VERSION ""

NS_ :

BS_:

BU_:
VAL_TABLE_ Parking_Light_VT 1 "Parking Lights Blinking" 0 "Parking lights OFF" ;
VAL_TABLE_ Indicator_Light_VT 1 "Left or Right Indicator ON" 0 "Left or Right Indicator OFF" ;
VAL_TABLE_ Ignition_Key_VT 3 "Car started" 2 "Pre-Ignition phase" 1 "Key Inserted" 0 "Key not inserted" ;
VAL_TABLE_ Engine_VT 1 "Engine RUNNING" 0 "Engine IDLE" ;
VAL_TABLE_ Brake_VT 1 "Brake Applied" 0 "Brake Not Applied" ;
VAL_TABLE_ Gear_VT 3 "Parking" 2 "Reverse" 1 "Drive" 0 "Neutral" ;

BO_ 260 Vehicle_Motion: 4 Vector__XXX
 SG_ Vehicle_Speed : 16|16@1+ (0.1,0) [0|6553.5] "m/s" Vector__XXX
 SG_ Engine_Status : 0|1@1+ (1,0) [0|1] "Boolean" Vector__XXX

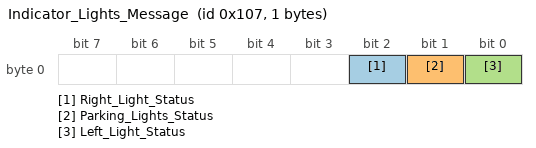
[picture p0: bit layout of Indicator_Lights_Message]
BO_ 263 Indicator_Lights_Message: 1 Vector__XXX
 SG_ Right_Light_Status : 2|1@1+ (1,0) [0|1] "Boolean" Vector__XXX
 SG_ Parking_Lights_Status : 1|1@1+ (1,0) [0|1] "Boolean" Vector__XXX
 SG_ Left_Light_Status : 0|1@1+ (1,0) [0|1] "Boolean" Vector__XXX

BO_ 258 Gear_Status: 1 Vector__XXX
 SG_ Gear_State : 0|2@1+ (1,0) [0|3] "" Vector__XXX

BO_ 259 Brake_Message: 1 Vector__XXX
 SG_ Brake_Signal : 0|1@1+ (1,0) [0|1] "Boolean" Vector__XXX

BO_ 261 Acceleraton_Message: 2 Vector__XXX
 SG_ Acceleration_Signal : 0|16@1+ (0.1,0) [0|6553.5] "m/s^2" Vector__XXX

BO_ 257 Ignition_Key: 1 Vector__XXX
 SG_ Ignition_Key_Status : 0|2@1+ (1,0) [0|3] "" Vector__XXX

VAL_ 260 Engine_Status 1 "Engine RUNNING" 0 "Engine IDLE" ;
VAL_ 263 Right_Light_Status 1 "Left or Right Indicator ON" 0 "Left or Right Indicator OFF" ;
VAL_ 263 Parking_Lights_Status 1 "Parking Lights Blinking" 0 "Parking lights OFF" ;
VAL_ 263 Left_Light_Status 1 "Left or Right Indicator ON" 0 "Left or Right Indicator OFF" ;
VAL_ 258 Gear_State 3 "Parking" 2 "Reverse" 1 "Drive" 0 "Neutral" ;
VAL_ 259 Brake_Signal 1 "Brake Applied" 0 "Brake Not Applied" ;
VAL_ 257 Ignition_Key_Status 3 "Car started" 2 "Pre-Ignition phase" 1 "Key Inserted" 0 "Key not inserted" ;
